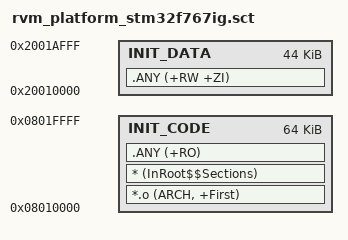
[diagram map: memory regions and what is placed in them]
;******************************************************************************
;Filename    : rvm_platform_STM32F767IG.sct
;Author      : The RME project generator.
;Date        : 07/10/2019
;Licence     : LGPL v3+; see COPYING for details.
;Description : The scatter file for ARMv7-M layout. This file is intended
;              to be used with STM32F767IG.
;******************************************************************************

; Begin Segment:INIT **********************************************************
; Description : The init segment, which contains the core of the user-level library.
; *****************************************************************************
INIT 0x8010000 0x10000
{
    ; The code segment of the INIT process
    INIT_CODE 0x8010000 0x10000
    {
        ; The entry will be the first instruction
        *.o                    (ARCH, +First)
        ; The lib code copying code
        *                      (InRoot$$Sections)
        ; The init code section
        .ANY                   (+RO)
    }

    ; The data section of the INIT process
    INIT_DATA 0x20010000 0xB000
    {
        .ANY                   (+RW +ZI)
    }
}
; End Segment:INIT ************************************************************

; End Of File *****************************************************************

; Copyright (C) Evo-Devo Instrum. All rights reserved *************************

